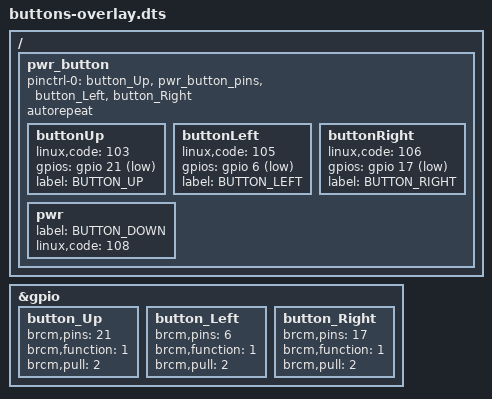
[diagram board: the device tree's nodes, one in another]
/dts-v1/;
/plugin/;

/ {
	fragment@0 {
		target = <&gpio>;
		__overlay__ {
			button_Up: button_Up {
				brcm,pins = <21>;
				brcm,function = <1>;
				brcm,pull = <2>;
			};
			button_Left: button_Left {
				brcm,pins = <6>;
				brcm,function = <1>;
				brcm,pull = <2>;
			};
			button_Right: button_Right {
				brcm,pins = <17>;
				brcm,function = <1>;
				brcm,pull = <2>;
			};
		};
	};

	fragment@1 {
		target-path = "/";
		__overlay__ {
			pwr_button {
				pinctrl-0 = <&button_Up &pwr_button_pins &button_Left &button_Right>;
				autorepeat;
				buttonUp: buttonUp {
					linux,code = <103>;
					gpios = <&gpio 21 1>;
					label = "BUTTON_UP";
				};
				buttonLeft: buttonLeft {
					linux,code = <105>;
					gpios = <&gpio 6 1>;
					label = "BUTTON_LEFT";
				};
				buttonRight: buttonRight {
					linux,code = <106>;
					gpios = <&gpio 17 1>;
					label = "BUTTON_RIGHT";
				};
				pwr {
					label = "BUTTON_DOWN";
					linux,code = <108>;
				};
			};
		};
	};
};
